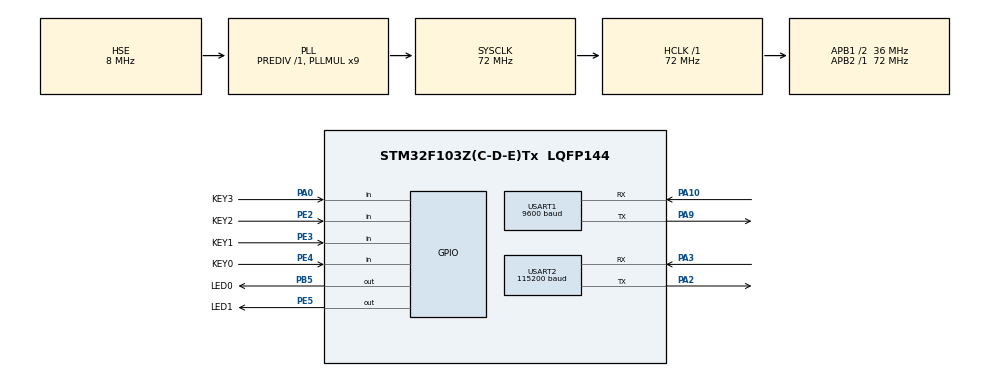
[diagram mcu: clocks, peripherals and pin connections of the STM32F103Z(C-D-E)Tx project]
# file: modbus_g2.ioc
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Mcu.Family=STM32F1
Mcu.Name=STM32F103Z(C-D-E)Tx
Mcu.Package=LQFP144
NVIC.PriorityGroup=NVIC_PRIORITYGROUP_4
NVIC.TIM6_IRQn=true\:0\:0\:false\:false\:true\:true\:true\:true
NVIC.TIM7_IRQn=true\:0\:0\:false\:false\:true\:true\:true\:true
NVIC.USART1_IRQn=true\:0\:0\:false\:false\:true\:true\:true\:true
OSC_IN.Mode=HSE-External-Oscillator
OSC_IN.Signal=RCC_OSC_IN
OSC_OUT.Mode=HSE-External-Oscillator
OSC_OUT.Signal=RCC_OSC_OUT
PA0-WKUP.GPIO_Label=KEY3
PA0-WKUP.GPIO_Mode=GPIO_MODE_INPUT
PA0-WKUP.GPIO_PuPd=GPIO_PULLDOWN
PA0-WKUP.Signal=GPIO_Input
PA10.Mode=Asynchronous
PA10.Signal=USART1_RX
PA13.Mode=Serial_Wire
PA13.Signal=SYS_JTMS-SWDIO
PA14.Mode=Serial_Wire
PA14.Signal=SYS_JTCK-SWCLK
PA2.Mode=Asynchronous
PA2.Signal=USART2_TX
PA3.Mode=Asynchronous
PA3.Signal=USART2_RX
PA9.Mode=Asynchronous
PA9.Signal=USART1_TX
PB5.GPIO_Label=LED0
PB5.PinState=GPIO_PIN_SET
PB5.Signal=GPIO_Output
PC14-OSC32_IN.Mode=LSE-External-Oscillator
PC14-OSC32_IN.Signal=RCC_OSC32_IN
PC15-OSC32_OUT.Mode=LSE-External-Oscillator
PC15-OSC32_OUT.Signal=RCC_OSC32_OUT
PE2.GPIO_Label=KEY2
PE2.GPIO_PuPd=GPIO_PULLUP
PE2.Signal=GPIO_Input
PE3.GPIO_Label=KEY1
PE3.GPIO_PuPd=GPIO_PULLUP
PE3.Signal=GPIO_Input
PE4.GPIO_Label=KEY0
PE4.GPIO_PuPd=GPIO_PULLUP
PE4.Signal=GPIO_Input
PE5.GPIO_Label=LED1
PE5.PinState=GPIO_PIN_SET
PE5.Signal=GPIO_Output
ProjectManager.HeapSize=0x200
ProjectManager.StackSize=0x400
ProjectManager.TargetToolchain=MDK-ARM V5.32
RCC.AHBFreq_Value=72000000
RCC.APB1CLKDivider=RCC_HCLK_DIV2
RCC.APB1Freq_Value=36000000
RCC.APB1TimFreq_Value=72000000
RCC.APB2Freq_Value=72000000
RCC.APB2TimFreq_Value=72000000
RCC.FLatency=FLASH_LATENCY_2
RCC.HCLKFreq_Value=72000000
RCC.PLLMUL=RCC_PLL_MUL9
RCC.PLLSourceVirtual=RCC_PLLSOURCE_HSE
RCC.SYSCLKFreq_VALUE=72000000
RCC.SYSCLKSource=RCC_SYSCLKSOURCE_PLLCLK
RCC.USBFreq_Value=72000000
TIM6.AutoReloadPreload=TIM_AUTORELOAD_PRELOAD_DISABLE
TIM6.CounterMode=TIM_COUNTERMODE_UP
TIM6.Period=39
TIM6.Prescaler=7199
TIM6.TIM_MasterOutputTrigger=TIM_TRGO_RESET
TIM7.AutoReloadPreload=TIM_AUTORELOAD_PRELOAD_DISABLE
TIM7.CounterMode=TIM_COUNTERMODE_UP
TIM7.Period=1999
TIM7.Prescaler=7199
TIM7.TIM_MasterOutputTrigger=TIM_TRGO_RESET
USART1.BaudRate=9600
USART1.Mode=MODE_TX_RX
USART1.Parity=PARITY_NONE
USART1.StopBits=STOPBITS_1
USART1.VirtualMode=VM_ASYNC
USART1.WordLength=WORDLENGTH_8B
USART2.BaudRate=115200
USART2.Mode=MODE_TX_RX
USART2.Parity=PARITY_NONE
USART2.StopBits=STOPBITS_1
USART2.VirtualMode=VM_ASYNC
USART2.WordLength=WORDLENGTH_8B
VP_TIM6_VS_ClockSourceINT.Mode=Enable_Timer
VP_TIM6_VS_OPM.Mode=OPM_bit
VP_TIM7_VS_ClockSourceINT.Mode=Enable_Timer
board=custom

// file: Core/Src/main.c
/* USER CODE BEGIN Header */
/**
  ******************************************************************************
  * @file           : main.c
  * @brief          : Main program body
  ******************************************************************************
  * @attention
  *
  * Copyright (c) 2025 STMicroelectronics.
  * All rights reserved.
  *
  * This software is licensed under terms that can be found in the LICENSE file
  * in the root directory of this software component.
  * If no LICENSE file comes with this software, it is provided AS-IS.
  *
  ******************************************************************************
  */
/* USER CODE END Header */
#include "main.h"
#include "tim.h"
#include "usart.h"
#include "gpio.h"

/* USER CODE BEGIN Includes */
#include "modbus.h"

/* USER CODE END Includes */

/* USER CODE BEGIN PV */
modbus_t modbus;
value_t value;

/* USER CODE END PV */

void SystemClock_Config(void);

int main(void)
{

  /* MCU Configuration--------------------------------------------------------*/

  /* Reset of all peripherals, Initializes the Flash interface and the Systick. */
  HAL_Init();

  /* Configure the system clock */
  SystemClock_Config();

  /* Initialize all configured peripherals */
  MX_GPIO_Init();
  MX_USART1_UART_Init();
  MX_TIM6_Init();
  MX_USART2_UART_Init();
  MX_TIM7_Init();
  /* USER CODE BEGIN 2 */
  HAL_UART_Receive_IT(&huart1, &modbus.rx_byte, 1);
  __HAL_TIM_SET_COUNTER(&htim6, 0);
  HAL_TIM_Base_Stop_IT(&htim6);
  HAL_TIM_Base_Start_IT(&htim7);
  value_init();

  /* USER CODE END 2 */

  /* Infinite loop */
  while (1)
  {

    /* USER CODE BEGIN 3 */
    modbus_handler();
    value_handler();

  }
  /* USER CODE END 3 */
}

void SystemClock_Config(void)
{
  RCC_OscInitTypeDef RCC_OscInitStruct = {0};
  RCC_ClkInitTypeDef RCC_ClkInitStruct = {0};

  /** Initializes the RCC Oscillators according to the specified parameters
  * in the RCC_OscInitTypeDef structure.
  */
  RCC_OscInitStruct.OscillatorType = RCC_OSCILLATORTYPE_HSE;
  RCC_OscInitStruct.HSEState = RCC_HSE_ON;
  RCC_OscInitStruct.HSEPredivValue = RCC_HSE_PREDIV_DIV1;
  RCC_OscInitStruct.HSIState = RCC_HSI_ON;
  RCC_OscInitStruct.PLL.PLLState = RCC_PLL_ON;
  RCC_OscInitStruct.PLL.PLLSource = RCC_PLLSOURCE_HSE;
  RCC_OscInitStruct.PLL.PLLMUL = RCC_PLL_MUL9;
  if (HAL_RCC_OscConfig(&RCC_OscInitStruct) != HAL_OK)
  {
    Error_Handler();
  }

  /** Initializes the CPU, AHB and APB buses clocks
  */
  RCC_ClkInitStruct.ClockType = RCC_CLOCKTYPE_HCLK|RCC_CLOCKTYPE_SYSCLK
                              |RCC_CLOCKTYPE_PCLK1|RCC_CLOCKTYPE_PCLK2;
  RCC_ClkInitStruct.SYSCLKSource = RCC_SYSCLKSOURCE_PLLCLK;
  RCC_ClkInitStruct.AHBCLKDivider = RCC_SYSCLK_DIV1;
  RCC_ClkInitStruct.APB1CLKDivider = RCC_HCLK_DIV2;
  RCC_ClkInitStruct.APB2CLKDivider = RCC_HCLK_DIV1;

  if (HAL_RCC_ClockConfig(&RCC_ClkInitStruct, FLASH_LATENCY_2) != HAL_OK)
  {
    Error_Handler();
  }
}

void Error_Handler(void)
{
  __disable_irq();
  while (1)
  {
  }
}
